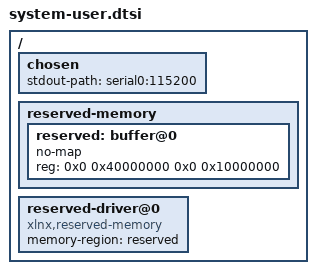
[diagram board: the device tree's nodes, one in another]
/include/ "system-conf.dtsi"
/  {
   chosen {
      stdout-path = "serial0:115200";
   };

   reserved-memory {
      #address-cells = <2>;
      #size-cells = <2>;
      ranges;

      reserved: buffer@0 {
         no-map;
         reg = <0x0 0x40000000 0x0 0x10000000>;
      };
   };

   reserved-driver@0 {
      compatible = "xlnx,reserved-memory";
      memory-region = <&reserved>;
   };
};
